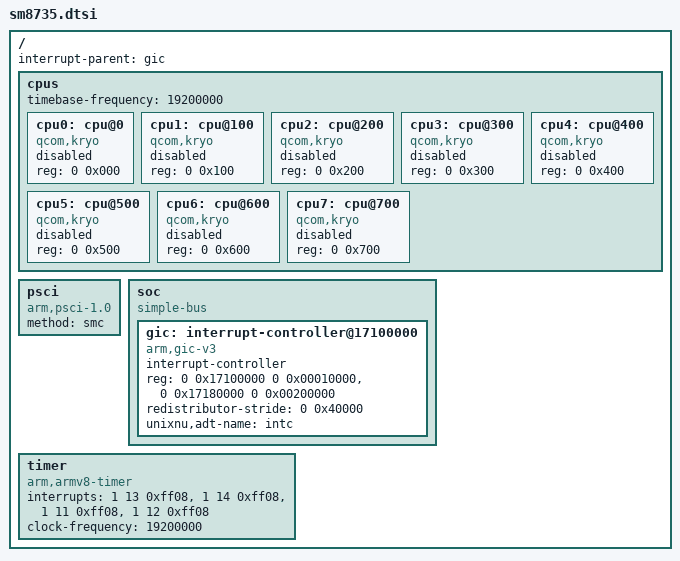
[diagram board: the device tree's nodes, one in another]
/* Minimal shared resources, transcribed from BOTH supplied stock base DTBs.
 * Revalidated on current Android 17 base DTBs and merges; see
 * ../../docs/CURRENT-ANDROID17.md (active) and STOCK-IMAGES.md (historical).
 * This is a UniXNU binding adaptation, NOT the full Android vendor tree.
 * No RAM, peripheral driver support, CPU microarchitecture or cluster split is inferred.
 */
/ {
    #address-cells = <2>;
    #size-cells = <2>;
    interrupt-parent = <&gic>;

    cpus {
        #address-cells = <2>;
        #size-cells = <0>;
        /* Stock /soc/timer clock-frequency, required on /cpus by the ADT converter. */
        timebase-frequency = <19200000>;
        cpu0: cpu@0 { device_type = "cpu"; compatible = "qcom,kryo"; reg = <0 0x000>; status = "disabled"; };
        cpu1: cpu@100 { device_type = "cpu"; compatible = "qcom,kryo"; reg = <0 0x100>; status = "disabled"; };
        cpu2: cpu@200 { device_type = "cpu"; compatible = "qcom,kryo"; reg = <0 0x200>; status = "disabled"; };
        cpu3: cpu@300 { device_type = "cpu"; compatible = "qcom,kryo"; reg = <0 0x300>; status = "disabled"; };
        cpu4: cpu@400 { device_type = "cpu"; compatible = "qcom,kryo"; reg = <0 0x400>; status = "disabled"; };
        cpu5: cpu@500 { device_type = "cpu"; compatible = "qcom,kryo"; reg = <0 0x500>; status = "disabled"; };
        cpu6: cpu@600 { device_type = "cpu"; compatible = "qcom,kryo"; reg = <0 0x600>; status = "disabled"; };
        cpu7: cpu@700 { device_type = "cpu"; compatible = "qcom,kryo"; reg = <0 0x700>; status = "disabled"; };
    };

    /* Relocated from Android /soc/psci to the top-level binding the converter reads. */
    psci { compatible = "arm,psci-1.0"; method = "smc"; };

    soc {
        compatible = "simple-bus";
        #address-cells = <2>;
        #size-cells = <2>;
        ranges;

        gic: interrupt-controller@17100000 {
            compatible = "arm,gic-v3";
            interrupt-controller;
            #interrupt-cells = <3>;
            #address-cells = <0>;
            reg = <0 0x17100000 0 0x00010000>,
                  <0 0x17180000 0 0x00200000>;
            redistributor-stride = <0 0x40000>;
            /* Export name is the exact /arm-io/intc path used by ArmCpu. */
            unixnu,adt-name = "intc";
        };
    };

    /* Interrupt tuple order and clock are retained from the stock timer binding.
     * ArmCpu itself uses the architectural virtual timer (PPI 11 / INTID 27).
     */
    timer {
        compatible = "arm,armv8-timer";
        interrupts = <1 13 0xff08>, <1 14 0xff08>, <1 11 0xff08>, <1 12 0xff08>;
        clock-frequency = <19200000>;
    };
};
